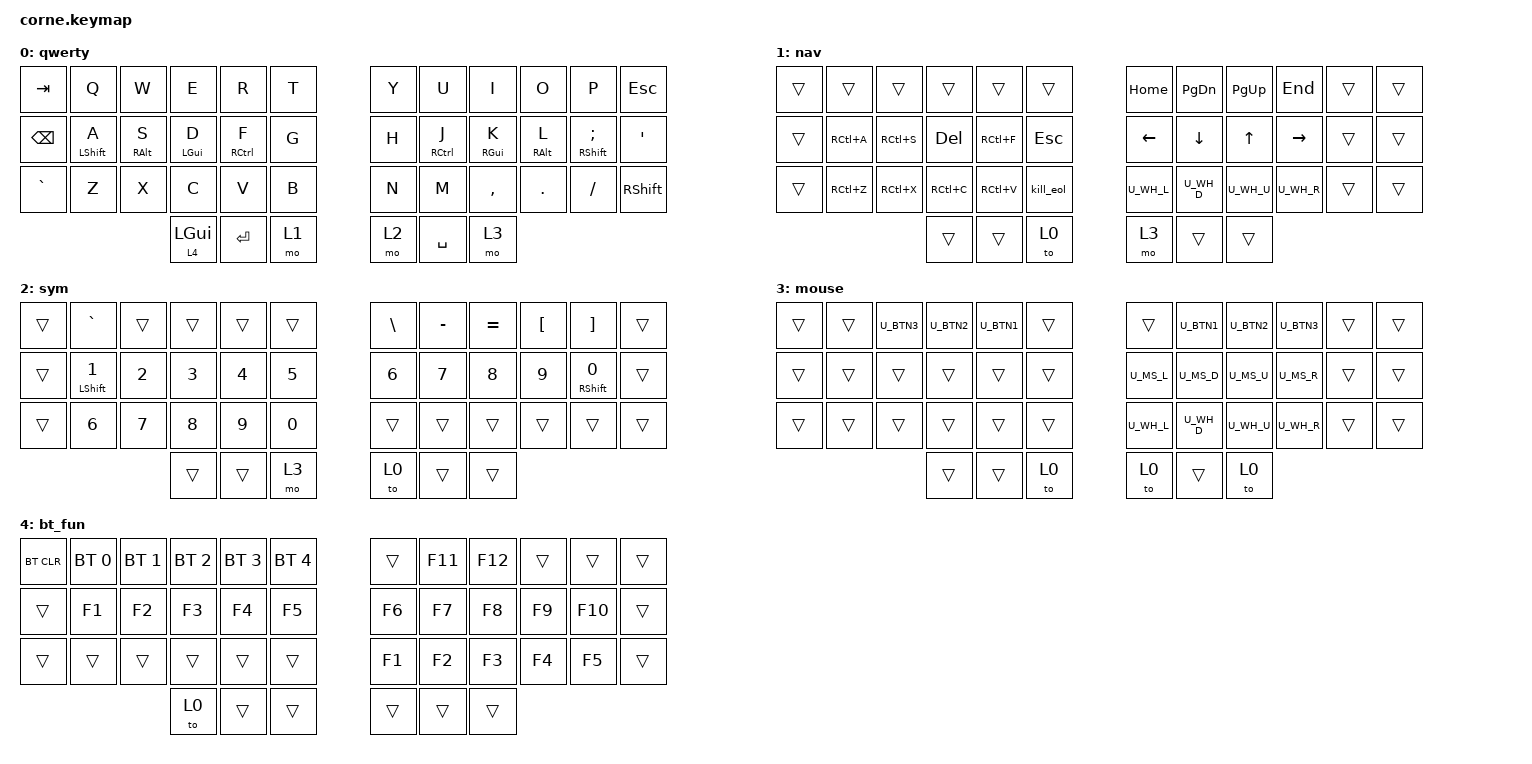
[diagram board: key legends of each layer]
/*
 * Copyright (c) 2020 The ZMK Contributors
 *
 * SPDX-License-Identifier: MIT
 */

#include <behaviors.dtsi>
#include <dt-bindings/zmk/keys.h>
#include <dt-bindings/zmk/bt.h>
#include "mouse.dtsi"

/ {
    macros {
        zed_em_kay: zed_em_kay {
            compatible = "zmk,behavior-macro";
            #binding-cells = <0>;
            bindings
                = <&macro_press &kp LSHFT>
                , <&macro_tap &kp Z &kp M &kp K>
                , <&macro_release &kp LSHFT>
                ;
        };
        kill_eol: kill_eol {
            compatible = "zmk,behavior-macro";
            #binding-cells = <0>;
            bindings
                = <&macro_press &kp LSHFT>
                , <&macro_tap &kp END>
                , <&macro_release &kp LSHFT>
                , <&macro_tap &kp RC(X)>
                ;
        };
    };
};

/ {
        behaviors {
            bhm: balanced_homerow_mods {
                compatible = "zmk,behavior-hold-tap";
                #binding-cells = <2>;
                tapping-term-ms = <150>;    // <---[[moderate duration]]
                quick-tap-ms = <0>;
                flavor = "balanced";
                bindings = <&kp>, <&kp>;
            };
        };
        keymap {
                compatible = "zmk,keymap";
                qwerty {
                        bindings = <
   &kp TAB   &kp Q             &kp W            &kp E       &kp R        &kp T      &kp Y  &kp U        &kp I       &kp O            &kp P                     &kp ESC
   &kp BSPC  &bhm LEFT_SHIFT A &bhm RIGHT_ALT S &bhm LGUI D &bhm RCTRL F &kp G      &kp H  &bhm RCTRL J &bhm RGUI K &bhm RIGHT_ALT L &bhm RIGHT_SHIFT SEMICOLON &kp SQT
   &kp GRAVE &kp Z             &kp X            &kp C       &kp V        &kp B      &kp N  &kp M        &kp COMMA   &kp DOT          &kp FSLH                  &kp RSHFT
                                                &lt 4 LGUI  &kp RET      &mo 1      &mo 2  &kp SPACE    &mo 3
                        >;
                };
                nav {
                        bindings = <
   &trans  &trans     &trans     &trans     &trans     &trans                       &kp HOME  &kp PG_DN  &kp PG_UP  &kp END    &trans  &trans
   &trans  &kp RC(A)  &kp RC(S)  &kp DEL    &kp RC(F)  &kp ESC                      &kp LEFT  &kp DOWN   &kp UP     &kp RIGHT  &trans  &trans
   &trans  &kp RC(Z)  &kp RC(X)  &kp RC(C)  &kp RC(V)  &kill_eol                    U_WH_L    U_WH_D     U_WH_U     U_WH_R     &trans  &trans
                                 &trans     &trans     &to 0                        &mo 3     &trans     &trans
                        >;
                };
                sym {
                        bindings = <
   &trans  &kp GRAVE                &trans  &trans  &trans  &trans                  &kp BSLH  &kp MINUS  &kp EQUAL  &kp LBKT  &kp RBKT                  &trans
   &trans  &bhm LEFT_SHIFT NUMBER_1 &kp N2  &kp N3  &kp N4  &kp N5                  &kp N6    &kp N7     &kp N8     &kp N9    &bhm RIGHT_SHIFT NUMBER_0 &trans
   &trans  &kp N6                   &kp N7  &kp N8  &kp N9  &kp N0                  &trans    &trans     &trans     &trans    &trans                    &trans
                                            &trans  &trans  &mo 3                   &to 0     &trans     &trans
                        >;
                };
                mouse {
                        bindings = <
   &trans  &trans  U_BTN3     U_BTN2     U_BTN1     &trans                          &trans  U_BTN1     U_BTN2     U_BTN3     &trans  &trans
   &trans  &trans  &trans     &trans     &trans     &trans                          U_MS_L  U_MS_D     U_MS_U     U_MS_R     &trans  &trans
   &trans  &trans  &trans     &trans     &trans     &trans                          U_WH_L  U_WH_D     U_WH_U     U_WH_R     &trans  &trans
                              &trans     &trans     &to 0                           &to 0   &trans     &to 0 
                        >;
                };
                bt_fun {
            bindings = <
   &bt BT_CLR  &bt BT_SEL 0  &bt BT_SEL 1  &bt BT_SEL 2  &bt BT_SEL 3  &bt BT_SEL 4 &trans  &kp F11  &kp F12  &trans  &trans   &trans
   &trans      &kp F1        &kp F2        &kp F3        &kp F4        &kp F5       &kp F6  &kp F7   &kp F8   &kp F9  &kp F10  &trans
   &trans      &trans        &trans        &trans        &trans        &trans       &kp F1  &kp F2   &kp F3   &kp F4  &kp F5   &trans
                                           &to 0         &trans        &trans       &trans  &trans   &trans
                        >;
                };
        };
};
